# DSS_DSP_PBIST register map
Vendor: Texas Instruments
Peripheral module from a debugger description file (folder awr2x44p).
Registers are 32-bit, read-write, no defined reset value unless marked. A register's access mark holds for its fields unless they carry their own. Offsets are as the file gives them; lines under a group give offsets from that group; [hi:lo] are bit positions; {n}, {i} and the like mark numbered series; 'fields as' and 'values as' point back to an identical list; <NAME> marks a mode.

## DSS_DSP_PBIST
{0x100+4i} PBIST_A{i} (i=0..3) — Variable Address Register{i}
  [15:0] PBIST_A{i} — TI Internal Register.Reserved for HW RnD
0x110 PBIST_L0 — Variable Loop Count Register L0
  [15:0] PBIST_L0 — TI Internal Register.Reserved for HW RnD Do not change this bit from its default value of 0
{0x110+4i} PBIST_L{i} (i=1..3) — Variable Loop Count Register L{i}
  [15:0] PBIST_L{i} — TI Internal Register.Reserved for HW RnD
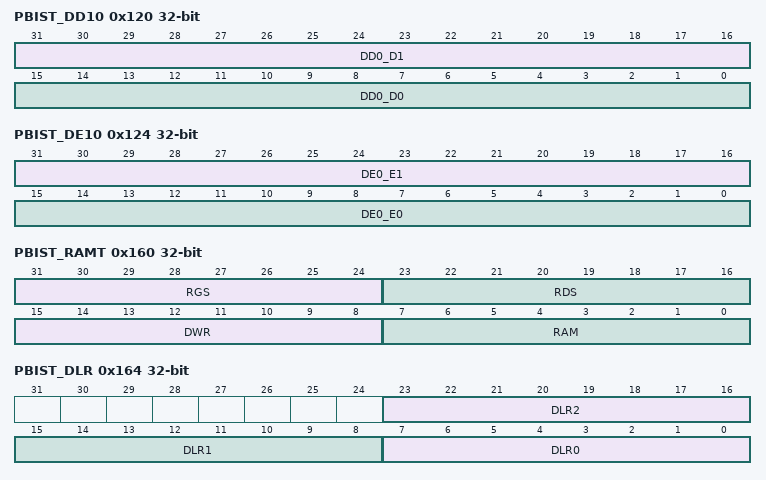
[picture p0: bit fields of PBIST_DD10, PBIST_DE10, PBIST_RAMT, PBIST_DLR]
0x120 PBIST_DD10 — DD0 Data Register 16 (D0)
  [31:16] DD0_D1 — TI Internal Register.Reserved for HW RnD
  [15:0] DD0_D0 — TI Internal Register.Reserved for HW RnD
0x124 PBIST_DE10 — DE0 Data Register 16 (D0)
  [31:16] DE0_E1 — TI Internal Register.Reserved for HW RnD
  [15:0] DE0_E0 — TI Internal Register.Reserved for HW RnD
{0x130+4i} PBIST_CA{i} (i=0..3) — Constant Address Register{i}
  [15:0] PBIST_CA{i} — TI Internal Register.Reserved for HW RnD
{0x140+4i} PBIST_CL{i} (i=0..3) — Constant Loop Count Register{i}
  [15:0] PBIST_CL{i} — TI Internal Register.Reserved for HW RnD
{0x150+4i} PBIST_CI{i} (i=0..3) — Constant Increment Register{i}
  [15:0] PBIST_CI{i} — TI Internal Register.Reserved for HW RnD
0x160 PBIST_RAMT — RAM Configuration (RAMT -RAM)
  [31:24] RGS — TI Internal Register.Reserved for HW RnD These registers do not have a default value after reset.
  [23:16] RDS — TI Internal Register.Reserved for HW RnD These registers do not have a default value after reset.
  [15:8] DWR — TI Internal Register.Reserved for HW RnD These registers do not have a default value after reset.
  [7:0] RAM — TI Internal Register.Reserved for HW RnD These registers do not have a default value after reset.
0x164 PBIST_DLR — Datalogger 0
  [23:16] DLR2 — TI Internal Register.Reserved for HW RnD
  [15:8] DLR1 — Datalogger Register [8] : Reserevd [9] : Default Testing Mode. When in this mode, ROM-based testing is kicked off. If the intention is to perform go/no-go testing via config, write to both this bit and bit [2] of the Datalogger Register simultaneously [15:10] : Reserevd
  [7:0] DLR0 — Datalogger Register [1:0] : Reserved [2] : ROM-based testing mode. Setting this bit to 1 enables the PBIST controller to execute test algorithms that are stored in the PBIST ROM [3] : Do not change this bit from its default value of 1 [4] : Config access mode. Setting this bit allows the host processor to configure the PBIST controller registers [7:5] : Reserved
0x168 PBIST_CMS — Clock mux select
  [3:0] PBIST_CMS — TI Internal Register.Reserved for HW RnD These registers do not have a default value after reset.
0x16C PBIST_PC — Program Control
  [4:0] PBIST_PC — TI Internal Register.Reserved for HW RnD
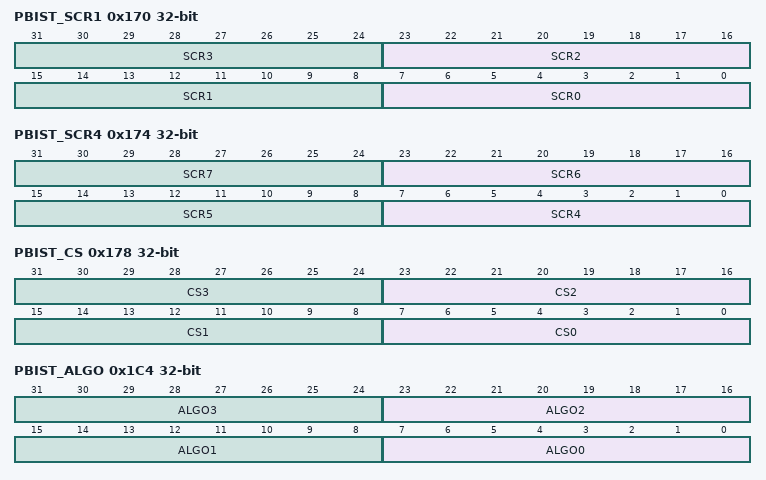
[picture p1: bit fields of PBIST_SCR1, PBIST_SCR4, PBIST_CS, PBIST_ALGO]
0x170 PBIST_SCR1 — Address Scramble 0 -3
  [8n+7:8n] SCR{n} (n=0..3) — TI Internal Register.Reserved for HW RnD
0x174 PBIST_SCR4 — Address Scramble 4-7
  [8n-25:8n-32] SCR{n} (n=4..7) — TI Internal Register.Reserved for HW RnD
0x178 PBIST_CS — Chip Select 0
  [8n+7:8n] CS{n} (n=0..3) — TI Internal Register.Reserved for HW RnD
0x17C PBIST_FDLY — Fail Delay
  [7:0] PBIST_FDLY — TI Internal Register.Reserved for HW RnD
0x180 PBIST_PACT — Pbist Active
  [0] PBIST_PACT — Pbist Active/ROM Clock Enable Register [0]: This bit must be set to turn on internal PBIST clocks. Setting this bit asserts an internal signal that is used as the clock gate enable. As long as this bit is 0, any access to PBIST will not go through, and PBIST will remain in an almost zero-power mode. Value 0 = Disable internal PBIST clocks Value 1 = Enable internal PBIST clocks
0x184 PBIST_ID
  [4:0] PBIST_ID — PBIST ID. This is a unique ID assigned to each PBIST controller in a device with multiple PBIST controllers. The value of this register does not affect the functionality of the CPU interface.
0x188 PBIST_OVR — PBIST Overrides
  [3:0] PBIST_OVR — PBIST Overrides. [0] : RINFO Override Bit While doing ROM-based testing, each algorithm downloaded from the ROM has a memory mask associated with it that defines the applicable memory groups the algorithm will be run on. By default, this bit is set to 1, which means the memory mask that is downloaded from the ROM will overwrite the RAM info registers. The override bit can be reset by writing a 0 to it. In this case, the application can select the RAM groups to be tested by configuring the RAM info registers. NOTE: When this override bit = 0, each algorithm selected in ALGO register will run on each RAM selected in RINFOL and RINFOU register. It must be ensured that: a. Only the same type of memories (single port or two port) are selected, and b. Only memories that are valid for all algorithms enabled via the ALGO register are selected. If the above two requirements are not met, the memory self-test will fail. [3:1] : Reserved. This bit must not be changed from its default value of 0.
0x190 PBIST_FSFR0 ro — Fail status fail - port 0
  [0] PBIST_FSFR0 — Fail Status Fail Register- Port 0 This register indicates if a failure occurred during a memory self-test. Value 0 = No failure occurred Value 1 = Indicates a failure
0x194 PBIST_FSFR1 ro — Fail status fail - port 1
  [0] PBIST_FSFR1 — Fail Status Fail Register- Port 1 This register indicates if a failure occurred during a memory self-test. Value 0 = No failure occurred Value 1 = Indicates a failure
0x198 PBIST_FSRCR0 ro — Fail Count fail - port 0
  [3:0] PBIST_FSRCR0 — Fail Status Count - Port 0 These registers keep count of the number of failures observed during the memory self-test. The PBIST controller stops executing the memory self-test whenever a failure occurs in any memory instance for any of the test algorithms. The value in gets incremented by one whenever a failure occurs
0x19C PBIST_FSRCR1 ro — Fail Count fail - port 1
  [3:0] PBIST_FSRCR1 — Fail Status Count - Port 1 These registers keep count of the number of failures observed during the memory self-test. The PBIST controller stops executing the memory self-test whenever a failure occurs in any memory instance for any of the test algorithms. The value in gets incremented by one whenever a failure occurs
0x1A0 PBIST_FSRA0 ro — Fail status address - port 0
  [15:0] PBIST_FSRA0 — TI Internal Register.Reserved for HW RnD
0x1A4 PBIST_FSRA1 ro — Fail status address - port 1
  [15:0] PBIST_FSRA1 — TI Internal Register.Reserved for HW RnD
0x1A8 PBIST_FSRDL0 ro — Fail status Data - port 0
  [31:0] PBIST_FSRDL0 — TI Internal Register.Reserved for HW RnD
0x1B0 PBIST_FSRDL1 ro — Fail status Data - port 1
  [31:0] PBIST_FSRDL1 — TI Internal Register.Reserved for HW RnD
0x1B4 PBIST_MARGIN ro — Margin Mode
0x1B8 PBIST_WRENZ ro — WRENZ
0x1BC PBIST_PGS ro — PAGE/PGS
0x1C0 PBIST_ROM — Rom Mask
  [1:0] PBIST_ROM — Rom Mask . This two-bit register sets appropriate ROM access modes for the PBIST controller. Value 0h = No information is used from ROM Value 1h = Only RAM Group information from ROM Vaule 2h = Only Algorithm information from ROM Value 3h = Both Algorithm and RAM information from ROM. This option should be selected for application self-test.
0x1C4 PBIST_ALGO — ROM Algorithm Mask 0
  [8n+7:8n] ALGO{n} (n=0..3) — This register is used to indicate the algorithm(s) to be used for the memory self-test routine. Each bit corresponds to a specific algorithm. Writing a value 1 to the particular bit, enables the corresponding algorithm. Writing a value 0 to the particular bit, disables the corresponding algorithm.
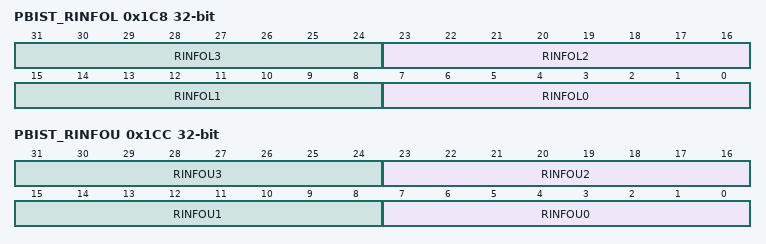
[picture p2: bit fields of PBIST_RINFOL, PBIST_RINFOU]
0x1C8 PBIST_RINFOL — RAM Info Mask Lower 0
  [8n+7:8n] RINFOL{n} (n=0..3) — This register is to select memory groups to run the algorithms selected in the PBIST_ALGO register. For an algorithmto be executed on a particular memory group, the corresponding bit in this register must be set to 1. The default value of this register is all 1s, which means all the memory groups are selected. Writing a value 0 to the particular bit, disables the corresponding memory group.
0x1CC PBIST_RINFOU — RAM Info Mask Upper 0
  [8n+7:8n] RINFOU{n} (n=0..3) — This register is to select memory groups to run the algorithms selected in the PBIST_ALGO register. For an algorithmto be executed on a particular memory group, the corresponding bit in this register must be set to 1. The default value of this register is all 1s, which means all the memory groups are selected. Writing a value 0 to the particular bit, disables the corresponding memory group.
